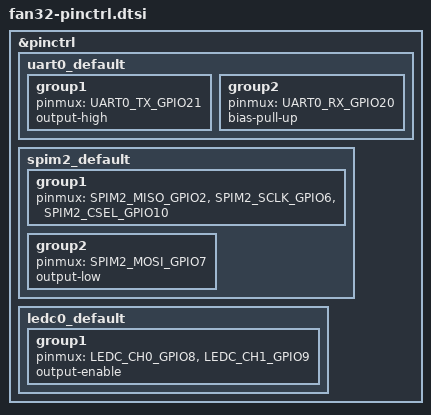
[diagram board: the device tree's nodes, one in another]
#include <zephyr/dt-bindings/pinctrl/esp-pinctrl-common.h>
#include <dt-bindings/pinctrl/esp32c3-pinctrl.h>
#include <zephyr/dt-bindings/pinctrl/esp32c3-gpio-sigmap.h>

&pinctrl {
	
	uart0_default: uart0_default {
		group1 {
			pinmux = <UART0_TX_GPIO21>;
			output-high;
		};
		group2 {
			pinmux = <UART0_RX_GPIO20>;
			bias-pull-up;
		};
	};
	
	spim2_default: spim2_default {
		group1 {
			pinmux = <SPIM2_MISO_GPIO2>,
			<SPIM2_SCLK_GPIO6>,
			<SPIM2_CSEL_GPIO10>;
		};
		group2 {
			pinmux = <SPIM2_MOSI_GPIO7>;
			output-low;
		};
	};
	ledc0_default: ledc0_default {
		group1 {
			pinmux = <LEDC_CH0_GPIO8>,// FAN1_PWM
			<LEDC_CH1_GPIO9>;// FAN0_PWM
			output-enable;
		};
	};
};
